# f29h85x_syncbridgempu_regs register map
Vendor: Texas Instruments
Peripheral module from a debugger description file (folder HSM).
Registers are 32-bit, read-write, no defined reset value unless marked. A register's access mark holds for its fields unless they carry their own. Offsets are as the file gives them; lines under a group give offsets from that group; [hi:lo] are bit positions; {n}, {i} and the like mark numbered series; 'fields as' and 'values as' point back to an identical list; <NAME> marks a mode.

## SYNCBRIDGEMPU_REGS — SYNCBRIDGEMPU Registers
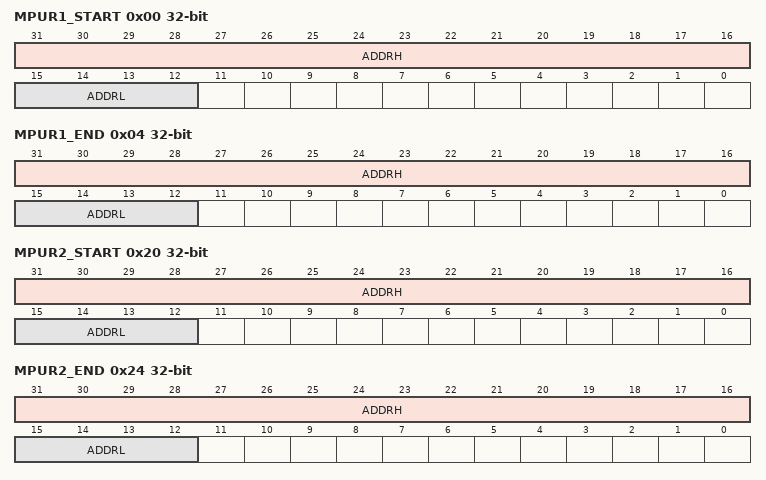
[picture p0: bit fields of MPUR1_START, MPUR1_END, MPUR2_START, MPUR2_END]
0x00 MPUR1_START — MPU Region 1 Start Address
  [31:16] ADDRH — Upper Start Address
  [15:12] ADDRL — Lower Start Address
0x04 MPUR1_END — MPU Region 1 End Address
  [31:16] ADDRH — Upper End Address
  [15:12] ADDRL — Lower End Address
0x08 MPUR1_LOCK — MPU 1 Temporary Lock
  [0] LOCK — Temporary Lock
0x0C MPUR1_COMMIT — MPU 1 Permanent Commit
  [0] COMMIT — Permanent Commit
0x10 MPUR1_ACCESS — MPU Region 1 R/W Access Permissions
  [1:0] ACCESS — Region Access Permissions
0x20 MPUR2_START — MPU Region 2 Start Address
  fields as MPUR1_START
0x24 MPUR2_END — MPU Region 2 End Address
  fields as MPUR1_END
0x28 MPUR2_LOCK — MPU 2 Temporary Lock
  [0] LOCK — Temporary Lock
0x2C MPUR2_COMMIT — MPU 2 Permanent Commit
  [0] COMMIT — Permanent Commit
0x30 MPUR2_ACCESS — MPU Region 2 R/W Access Permissions
  [1:0] ACCESS — Region Access Permissions
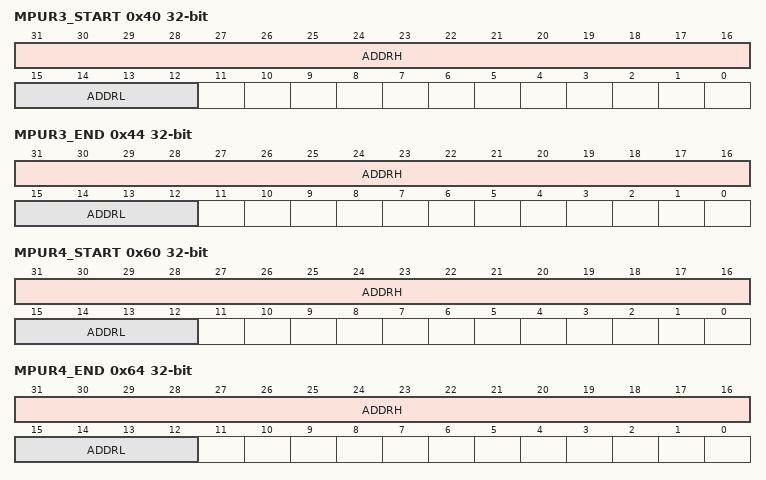
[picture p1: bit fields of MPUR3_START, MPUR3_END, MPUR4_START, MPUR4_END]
0x40 MPUR3_START — MPU Region 3 Start Address
  fields as MPUR1_START
0x44 MPUR3_END — MPU Region 3 End Address
  fields as MPUR1_END
0x48 MPUR3_LOCK — MPU 3 Temporary Lock
  [0] LOCK — Temporary Lock
0x4C MPUR3_COMMIT — MPU 3 Permanent Commit
  [0] COMMIT — Permanent Commit
0x50 MPUR3_ACCESS — MPU Region 3 R/W Access Permissions
  [1:0] ACCESS — Region Access Permissions
0x60 MPUR4_START — MPU Region 4 Start Address
  fields as MPUR1_START
0x64 MPUR4_END — MPU Region 4 End Address
  fields as MPUR1_END
0x68 MPUR4_LOCK — MPU 4 Temporary Lock
  [0] LOCK — Temporary Lock
0x6C MPUR4_COMMIT — MPU 4 Permanent Commit
  [0] COMMIT — Permanent Commit
0x70 MPUR4_ACCESS — MPU Region 4 R/W Access Permissions
  [1:0] ACCESS — Region Access Permissions
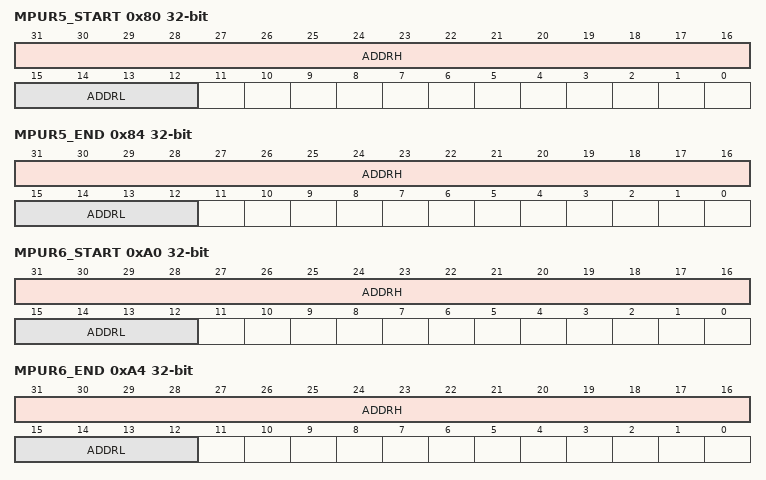
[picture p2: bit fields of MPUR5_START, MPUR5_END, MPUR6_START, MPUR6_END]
0x80 MPUR5_START — MPU Region 5 Start Address
  fields as MPUR1_START
0x84 MPUR5_END — MPU Region 5 End Address
  fields as MPUR1_END
0x88 MPUR5_LOCK — MPU 5 Temporary Lock
  [0] LOCK — Temporary Lock
0x8C MPUR5_COMMIT — MPU 5 Permanent Commit
  [0] COMMIT — Permanent Commit
0x90 MPUR5_ACCESS — MPU Region 5 R/W Access Permissions
  [1:0] ACCESS — Region Access Permissions
0xA0 MPUR6_START — MPU Region 6 Start Address
  fields as MPUR1_START
0xA4 MPUR6_END — MPU Region 6 End Address
  fields as MPUR1_END
0xA8 MPUR6_LOCK — MPU 6 Temporary Lock
  [0] LOCK — Temporary Lock
0xAC MPUR6_COMMIT — MPU 6 Permanent Commit
  [0] COMMIT — Permanent Commit
0xB0 MPUR6_ACCESS — MPU Region 6 R/W Access Permissions
  [1:0] ACCESS — Region Access Permissions
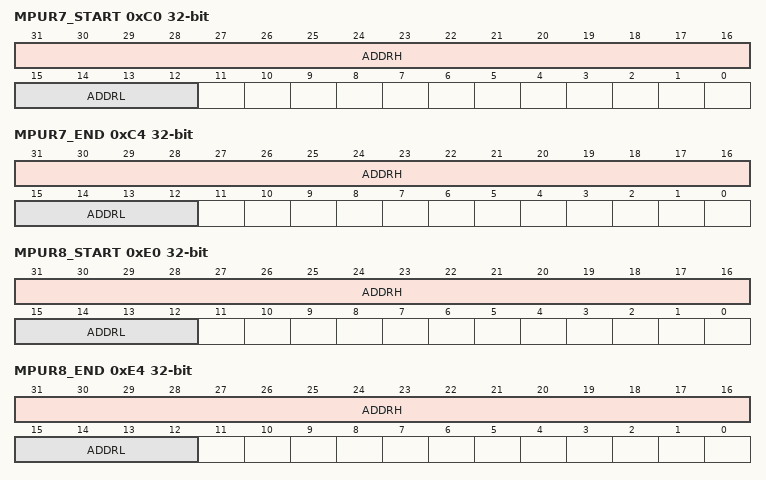
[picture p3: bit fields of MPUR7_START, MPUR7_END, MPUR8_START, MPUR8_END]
0xC0 MPUR7_START — MPU Region 7 Start Address
  fields as MPUR1_START
0xC4 MPUR7_END — MPU Region 7 End Address
  fields as MPUR1_END
0xC8 MPUR7_LOCK — MPU 7 Temporary Lock
  [0] LOCK — Temporary Lock
0xCC MPUR7_COMMIT — MPU 7 Permanent Commit
  [0] COMMIT — Permanent Commit
0xD0 MPUR7_ACCESS — MPU Region 7 R/W Access Permissions
  [1:0] ACCESS — Region Access Permissions
0xE0 MPUR8_START — MPU Region 8 Start Address
  fields as MPUR1_START
0xE4 MPUR8_END — MPU Region 8 End Address
  fields as MPUR1_END
0xE8 MPUR8_LOCK — MPU 8 Temporary Lock
  [0] LOCK — Temporary Lock
0xEC MPUR8_COMMIT — MPU 8 Permanent Commit
  [0] COMMIT — Permanent Commit
0xF0 MPUR8_ACCESS — MPU Region 8 R/W Access Permissions
  [1:0] ACCESS — Region Access Permissions
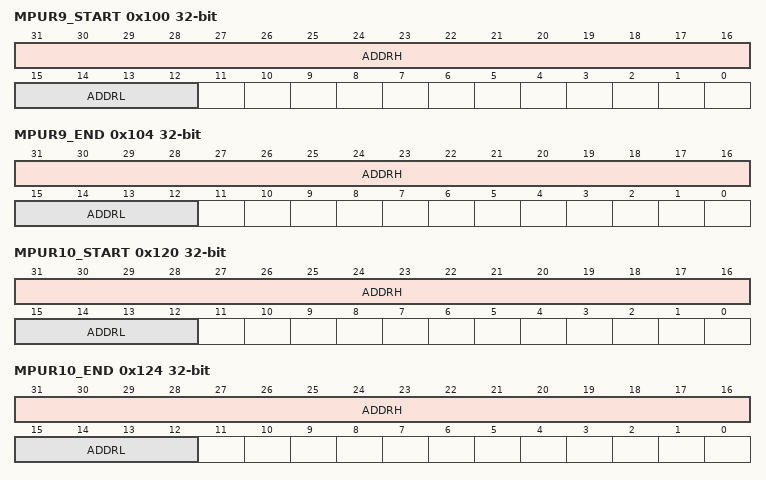
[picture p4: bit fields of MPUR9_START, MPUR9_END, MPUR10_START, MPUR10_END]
0x100 MPUR9_START — MPU Region 9 Start Address
  fields as MPUR1_START
0x104 MPUR9_END — MPU Region 9 End Address
  fields as MPUR1_END
0x108 MPUR9_LOCK — MPU 9 Temporary Lock
  [0] LOCK — Temporary Lock
0x10C MPUR9_COMMIT — MPU 9 Permanent Commit
  [0] COMMIT — Permanent Commit
0x110 MPUR9_ACCESS — MPU Region 9 R/W Access Permissions
  [1:0] ACCESS — Region Access Permissions
0x120 MPUR10_START — MPU Region 10 Start Address
  fields as MPUR1_START
0x124 MPUR10_END — MPU Region 10 End Address
  fields as MPUR1_END
0x128 MPUR10_LOCK — MPU 10 Temporary Lock
  [0] LOCK — Temporary Lock
0x12C MPUR10_COMMIT — MPU 10 Permanent Commit
  [0] COMMIT — Permanent Commit
0x130 MPUR10_ACCESS — MPU Region 10 R/W Access Permissions
  [1:0] ACCESS — Region Access Permissions
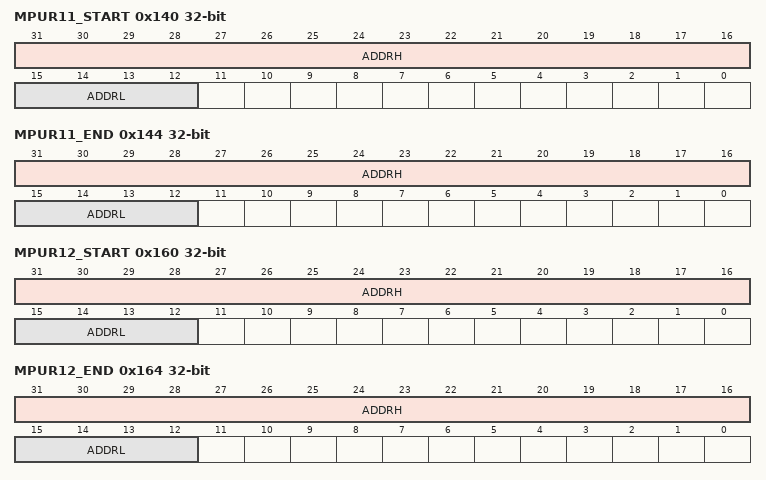
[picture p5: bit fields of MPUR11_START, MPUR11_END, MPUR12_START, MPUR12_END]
0x140 MPUR11_START — MPU Region 11 Start Address
  fields as MPUR1_START
0x144 MPUR11_END — MPU Region 11 End Address
  fields as MPUR1_END
0x148 MPUR11_LOCK — MPU 11 Temporary Lock
  [0] LOCK — Temporary Lock
0x14C MPUR11_COMMIT — MPU 11 Permanent Commit
  [0] COMMIT — Permanent Commit
0x150 MPUR11_ACCESS — MPU Region 11 R/W Access Permissions
  [1:0] ACCESS — Region Access Permissions
0x160 MPUR12_START — MPU Region 12 Start Address
  fields as MPUR1_START
0x164 MPUR12_END — MPU Region 12 End Address
  fields as MPUR1_END
0x168 MPUR12_LOCK — MPU 12 Temporary Lock
  [0] LOCK — Temporary Lock
0x16C MPUR12_COMMIT — MPU 12 Permanent Commit
  [0] COMMIT — Permanent Commit
0x170 MPUR12_ACCESS — MPU Region 12 R/W Access Permissions
  [1:0] ACCESS — Region Access Permissions
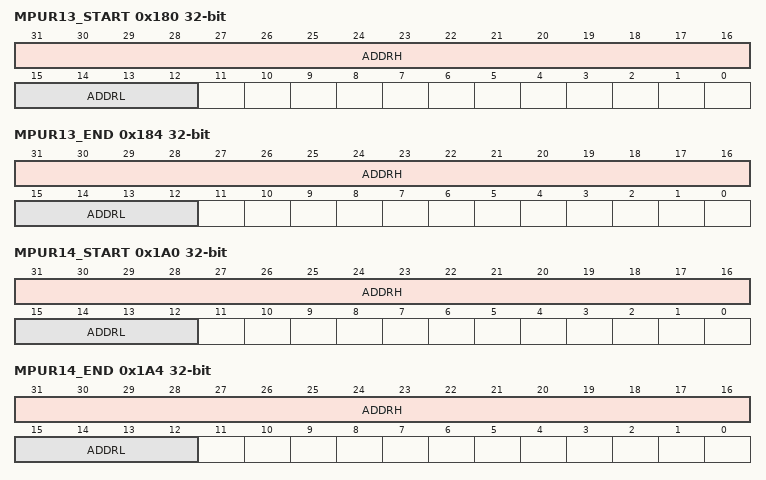
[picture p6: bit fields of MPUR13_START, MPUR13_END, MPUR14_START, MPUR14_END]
0x180 MPUR13_START — MPU Region 13 Start Address
  fields as MPUR1_START
0x184 MPUR13_END — MPU Region 13 End Address
  fields as MPUR1_END
0x188 MPUR13_LOCK — MPU 13 Temporary Lock
  [0] LOCK — Temporary Lock
0x18C MPUR13_COMMIT — MPU 13 Permanent Commit
  [0] COMMIT — Permanent Commit
0x190 MPUR13_ACCESS — MPU Region 13 R/W Access Permissions
  [1:0] ACCESS — Region Access Permissions
0x1A0 MPUR14_START — MPU Region 14 Start Address
  fields as MPUR1_START
0x1A4 MPUR14_END — MPU Region 14 End Address
  fields as MPUR1_END
0x1A8 MPUR14_LOCK — MPU 14 Temporary Lock
  [0] LOCK — Temporary Lock
0x1AC MPUR14_COMMIT — MPU 14 Permanent Commit
  [0] COMMIT — Permanent Commit
0x1B0 MPUR14_ACCESS — MPU Region 14 R/W Access Permissions
  [1:0] ACCESS — Region Access Permissions
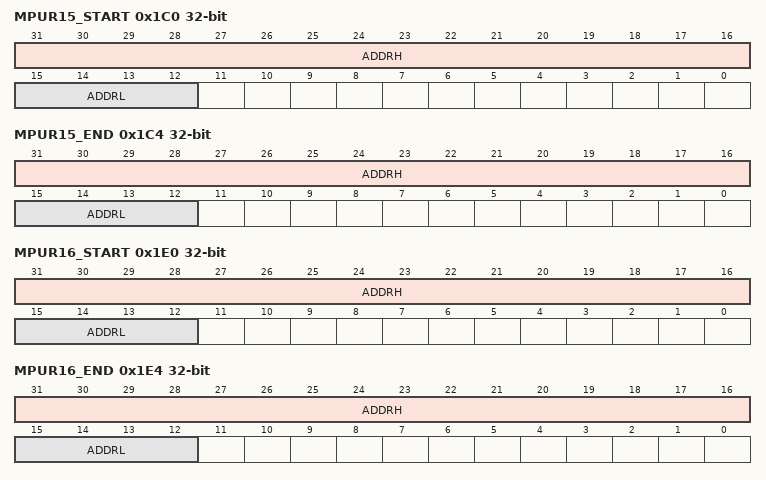
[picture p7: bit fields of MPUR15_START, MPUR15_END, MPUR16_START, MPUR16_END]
0x1C0 MPUR15_START — MPU Region 15 Start Address
  fields as MPUR1_START
0x1C4 MPUR15_END — MPU Region 15 End Address
  fields as MPUR1_END
0x1C8 MPUR15_LOCK — MPU 15 Temporary Lock
  [0] LOCK — Temporary Lock
0x1CC MPUR15_COMMIT — MPU 15 Permanent Commit
  [0] COMMIT — Permanent Commit
0x1D0 MPUR15_ACCESS — MPU Region 15 R/W Access Permissions
  [1:0] ACCESS — Region Access Permissions
0x1E0 MPUR16_START — MPU Region 16 Start Address
  fields as MPUR1_START
0x1E4 MPUR16_END — MPU Region 16 End Address
  fields as MPUR1_END
0x1E8 MPUR16_LOCK — MPU 16 Temporary Lock
  [0] LOCK — Temporary Lock
0x1EC MPUR16_COMMIT — MPU 16 Permanent Commit
  [0] COMMIT — Permanent Commit
0x1F0 MPUR16_ACCESS — MPU Region 16 R/W Access Permissions
  [1:0] ACCESS — Region Access Permissions
0x7FC MPUCTRL — MPU Control Register
  [0] MPUEN — Enable MPU function
0x81C MPUCFG_LOCK — Channel Configuration Temporary Lock
  [0] LOCK — Temporary Lock
0x820 MPUCFG_COMMIT — Channel Configuration Permanent Commit
  [0] COMMIT — Permanent Commit
